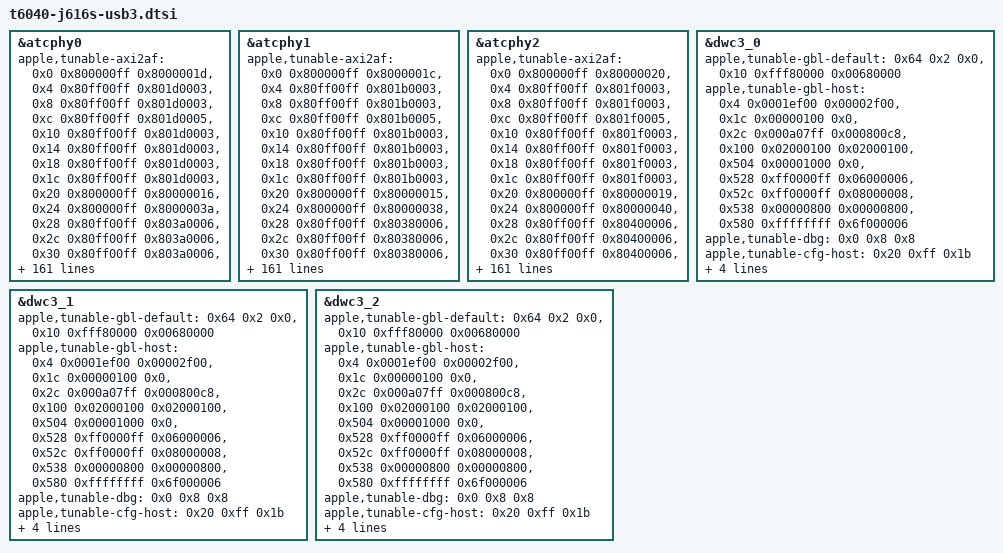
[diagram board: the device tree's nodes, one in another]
// SPDX-License-Identifier: GPL-2.0+ OR MIT
/*
 * USB3 tunables of the J616s Type-C ports, from this machine's ADT (macOS 26.6.2, 2026-10-16):
 * the atc-phyN tables AppleT6040TypeCPhy applies at every USB3 power-on, relative to the PHY
 * region each one targets, and the usb-drdN controller tables (identical on the three ports).
 * Entries are <offset mask value>: new = (old & ~mask) | value.
 */

&atcphy0 {
	apple,tunable-axi2af =
		<0x0 0x800000ff 0x8000001d>,
		<0x4 0x80ff00ff 0x801d0003>,
		<0x8 0x80ff00ff 0x801d0003>,
		<0xc 0x80ff00ff 0x801d0005>,
		<0x10 0x80ff00ff 0x801d0003>,
		<0x14 0x80ff00ff 0x801d0003>,
		<0x18 0x80ff00ff 0x801d0003>,
		<0x1c 0x80ff00ff 0x801d0003>,
		<0x20 0x800000ff 0x80000016>,
		<0x24 0x800000ff 0x8000003a>,
		<0x28 0x80ff00ff 0x803a0006>,
		<0x2c 0x80ff00ff 0x803a0006>,
		<0x30 0x80ff00ff 0x803a0006>,
		<0x34 0x80ff00ff 0x803a0006>,
		<0x38 0x80ff00ff 0x803a0006>,
		<0x3c 0x80ff00ff 0x803a0006>,
		<0x40 0x800000ff 0x80000016>,
		<0x44 0x800000ff 0x80000016>,
		<0x48 0x800000ff 0x80000016>,
		<0x100 0x000000ff 0x000000ff>,
		<0x108 0xffff0006 0x00100000>,
		<0x304 0x3f3f0000 0x04040000>,
		<0x308 0x000fffff 0x00001681>,
		<0x30c 0x000fffff 0x00001680>,
		<0x310 0x70000fff 0x000001e0>,
		<0x314 0xf0000fff 0x800001e0>,
		<0x318 0x70000fff 0x000001e0>,
		<0x31c 0xf0000fff 0x800001e0>,
		<0x320 0x70000fff 0x000005a0>,
		<0x324 0xf0000fff 0x800005a0>,
		<0x328 0x70000fff 0x000005a0>,
		<0x32c 0xf0000fff 0x800005a0>,
		<0x330 0x70000fff 0x000005a0>,
		<0x334 0xf0000fff 0x800005a0>,
		<0x338 0x70000fff 0x000005a0>,
		<0x33c 0x70000fff 0x000005a0>,
		<0x340 0x70000fff 0x000005a0>,
		<0x344 0x70000fff 0x000005a0>,
		<0x348 0x70000fff 0x000005a0>,
		<0x34c 0x70000fff 0x000005a0>,
		<0x350 0x70000fff 0x000005a0>,
		<0x358 0xffffffff 0x0000ffff>,
		<0x35c 0xffffffff 0x0000ffff>,
		<0x408 0xffff0020 0x00190020>,
		<0x40c 0x000fffff 0x00001681>,
		<0x410 0x000fffff 0x00001680>,
		<0x414 0x70000fff 0x000001e0>,
		<0x418 0x70000fff 0x000001e0>,
		<0x41c 0x70000fff 0x000001e0>,
		<0x420 0x70000fff 0x000001e0>,
		<0x424 0x70000fff 0x000005a0>,
		<0x428 0x70000fff 0x000005a0>,
		<0x42c 0x70000fff 0x000005a0>,
		<0x430 0x70000fff 0x000005a0>,
		<0x434 0x70000fff 0x000005a0>,
		<0x438 0x70000fff 0x000005a0>,
		<0x43c 0x70000fff 0x000005a0>,
		<0x440 0x70000fff 0x000005a0>,
		<0x444 0x70000fff 0x000005a0>,
		<0x448 0x70000fff 0x000005a0>,
		<0x44c 0x70000fff 0x000005a0>,
		<0x450 0x70000fff 0x000005a0>,
		<0x454 0x70000fff 0x000005a0>,
		<0x948 0x07ff07ff 0x00280000>,
		<0xa48 0x07ff07ff 0x00400040>,
		<0xb48 0x07ff07ff 0x00b8010e>,
		<0xc48 0x07ff07ff 0x00400020>,
		<0xd48 0x07ff07ff 0x008a008a>,
		<0x1000 0xffffffff 0x7fffffff>,
		<0x4008 0x00000001 0x00000001>,
		<0x400c 0x00000001 0x00000001>,
		<0x4014 0x00000001 0x00000001>,
		<0x4018 0x00000001 0x00000000>,
		<0x401c 0x00000001 0x00000001>;
	apple,tunable-fabric =
		<0x4 0x003f003f 0x00200020>,
		<0xc 0x000000f1 0x000000a1>,
		<0x10 0x0000801f 0x00000004>,
		<0x18 0x003f003f 0x00200020>,
		<0x20 0x000000f1 0x000000a1>,
		<0x24 0x0000801f 0x00000004>,
		<0x2c 0x00ff00ff 0x00960096>,
		<0x34 0x000000f1 0x00000071>,
		<0x38 0x0000801f 0x00000004>,
		<0x40 0x0000003f 0x00000020>,
		<0x48 0x0000801f 0x00000004>,
		<0x50 0x007f007f 0x00450045>,
		<0x58 0x0000801f 0x00000004>,
		<0x60 0x0000003f 0x00000020>,
		<0x68 0x0000801f 0x00000004>,
		<0x70 0x00000001 0x00000001>,
		<0x74 0x0000801f 0x00000004>,
		<0x7c 0x007f007f 0x00400040>,
		<0x80 0x000000f1 0x00000011>,
		<0x84 0x00000001 0x00000001>,
		<0x88 0x00000001 0x00000001>,
		<0x8c 0x0000801f 0x00000004>,
		<0x94 0x001f001f 0x00100010>,
		<0x98 0x000000f1 0x00000011>,
		<0x9c 0x0000801f 0x00000004>,
		<0xa4 0x000000ff 0x000000e0>,
		<0xa8 0x0000801f 0x00000004>,
		<0xb0 0x0000003f 0x00000020>,
		<0xb8 0x0000801f 0x00000004>,
		<0xc0 0x0000003f 0x00000020>,
		<0xc8 0x0000801f 0x00000004>,
		<0xd0 0x001f001f 0x00100010>,
		<0xd8 0x00000001 0x00000001>,
		<0xdc 0x00000001 0x00000001>,
		<0xe0 0x0000801f 0x00000004>,
		<0xe8 0x0000000f 0x00000008>,
		<0xec 0x0000801f 0x00000004>,
		<0xf4 0xffffffff 0x01010101>,
		<0xf8 0x0000801f 0x00000004>,
		<0x100 0x00000001 0x00000001>,
		<0x104 0x00000001 0x00000001>,
		<0x108 0x0000801f 0x00000004>,
		<0x110 0x0000801f 0x00000004>,
		<0x118 0x0000801f 0x00000004>,
		<0x120 0x00000001 0x00000001>,
		<0x124 0x00000001 0x00000001>,
		<0x128 0x0000801f 0x00000004>,
		<0x130 0xffffffff 0x01010101>,
		<0x134 0x0000801f 0x00000004>,
		<0x13c 0x00000001 0x00000001>,
		<0x140 0x00000001 0x00000001>,
		<0x144 0x0000801f 0x00000004>,
		<0x14c 0x00000001 0x00000001>,
		<0x150 0x00000001 0x00000001>,
		<0x154 0x0000801f 0x00000004>,
		<0x15c 0x0000801f 0x00000004>,
		<0x164 0xffffffff 0x01010101>,
		<0x168 0x0000ffff 0x00000101>,
		<0x16c 0x0000801f 0x00000004>,
		<0x174 0x00000001 0x00000001>,
		<0x178 0x00000001 0x00000001>,
		<0x17c 0x0000801f 0x00000004>,
		<0x184 0x00000001 0x00000001>,
		<0x188 0x00000001 0x00000001>,
		<0x18c 0x0000801f 0x00000004>;
	apple,tunable-common-cfg =
		<0x8 0x00000001 0x00000001>;
	apple,tunable-axi2af-lioa =
		<0x28 0x0000fe2f 0x00000000>,
		<0x2c 0x00000007 0x00000000>,
		<0x30 0x0000007f 0x00000000>,
		<0x34 0x000000ff 0x00000000>,
		<0x58 0x0000010b 0x00000000>;
	apple,tunable-lane0 =
		<0xd094 0x00080000 0x00080000>,
		<0xd098 0x00080000 0x00080000>,
		<0xd0a4 0x00800000 0x00800000>,
		<0xd0a8 0x00200000 0x00200000>;
	apple,tunable-lane1 =
		<0x1d094 0x00080000 0x00080000>,
		<0x1d098 0x00080000 0x00080000>,
		<0x1d0a4 0x00800000 0x00800000>,
		<0x1d0a8 0x00200000 0x00200000>;
	apple,tunable-aus40cmn-shm =
		<0xa04 0x0000007c 0x00000048>;
	apple,tunable-auspll =
		<0x3224 0x00000c00 0x00000800>,
		<0x3230 0x0000001f 0x0000000f>,
		<0x3240 0x07d8007f 0x04000059>,
		<0x32b0 0x0b800000 0x01800000>,
		<0x32e8 0x00060001 0x00040001>,
		<0x3338 0x0f800000 0x07800000>;
	apple,tunable-cio4pll =
		<0x3a30 0x0000001f 0x0000000f>,
		<0x3a4c 0x0000fe7f 0x0000501e>,
		<0x3ab0 0x00700000 0x00300000>,
		<0x3ae8 0x00060000 0x00020000>;
	apple,tunable-pipehandler = <0x44 0x4 0x4>;
	/* ADT tunable_USB2PHY_HOST, relative to USB2 bank 0. */
	apple,tunable-usb2-host = <0x8 0x7003 0x3>;
};

&atcphy1 {
	apple,tunable-axi2af =
		<0x0 0x800000ff 0x8000001c>,
		<0x4 0x80ff00ff 0x801b0003>,
		<0x8 0x80ff00ff 0x801b0003>,
		<0xc 0x80ff00ff 0x801b0005>,
		<0x10 0x80ff00ff 0x801b0003>,
		<0x14 0x80ff00ff 0x801b0003>,
		<0x18 0x80ff00ff 0x801b0003>,
		<0x1c 0x80ff00ff 0x801b0003>,
		<0x20 0x800000ff 0x80000015>,
		<0x24 0x800000ff 0x80000038>,
		<0x28 0x80ff00ff 0x80380006>,
		<0x2c 0x80ff00ff 0x80380006>,
		<0x30 0x80ff00ff 0x80380006>,
		<0x34 0x80ff00ff 0x80380006>,
		<0x38 0x80ff00ff 0x80380006>,
		<0x3c 0x80ff00ff 0x80380006>,
		<0x40 0x800000ff 0x80000015>,
		<0x44 0x800000ff 0x80000015>,
		<0x48 0x800000ff 0x80000015>,
		<0x100 0x000000ff 0x000000ff>,
		<0x108 0xffff0006 0x00100000>,
		<0x304 0x3f3f0000 0x04040000>,
		<0x308 0x000fffff 0x00001681>,
		<0x30c 0x000fffff 0x00001680>,
		<0x310 0x70000fff 0x000001e0>,
		<0x314 0xf0000fff 0x800001e0>,
		<0x318 0x70000fff 0x000001e0>,
		<0x31c 0xf0000fff 0x800001e0>,
		<0x320 0x70000fff 0x000005a0>,
		<0x324 0xf0000fff 0x800005a0>,
		<0x328 0x70000fff 0x000005a0>,
		<0x32c 0xf0000fff 0x800005a0>,
		<0x330 0x70000fff 0x000005a0>,
		<0x334 0xf0000fff 0x800005a0>,
		<0x338 0x70000fff 0x000005a0>,
		<0x33c 0x70000fff 0x000005a0>,
		<0x340 0x70000fff 0x000005a0>,
		<0x344 0x70000fff 0x000005a0>,
		<0x348 0x70000fff 0x000005a0>,
		<0x34c 0x70000fff 0x000005a0>,
		<0x350 0x70000fff 0x000005a0>,
		<0x358 0xffffffff 0x0000ffff>,
		<0x35c 0xffffffff 0x0000ffff>,
		<0x408 0xffff0020 0x00180020>,
		<0x40c 0x000fffff 0x00001681>,
		<0x410 0x000fffff 0x00001680>,
		<0x414 0x70000fff 0x000001e0>,
		<0x418 0x70000fff 0x000001e0>,
		<0x41c 0x70000fff 0x000001e0>,
		<0x420 0x70000fff 0x000001e0>,
		<0x424 0x70000fff 0x000005a0>,
		<0x428 0x70000fff 0x000005a0>,
		<0x42c 0x70000fff 0x000005a0>,
		<0x430 0x70000fff 0x000005a0>,
		<0x434 0x70000fff 0x000005a0>,
		<0x438 0x70000fff 0x000005a0>,
		<0x43c 0x70000fff 0x000005a0>,
		<0x440 0x70000fff 0x000005a0>,
		<0x444 0x70000fff 0x000005a0>,
		<0x448 0x70000fff 0x000005a0>,
		<0x44c 0x70000fff 0x000005a0>,
		<0x450 0x70000fff 0x000005a0>,
		<0x454 0x70000fff 0x000005a0>,
		<0x948 0x07ff07ff 0x00280000>,
		<0xa48 0x07ff07ff 0x00400040>,
		<0xb48 0x07ff07ff 0x00b8010e>,
		<0xc48 0x07ff07ff 0x00400020>,
		<0xd48 0x07ff07ff 0x008a008a>,
		<0x1000 0xffffffff 0x7fffffff>,
		<0x4008 0x00000001 0x00000001>,
		<0x400c 0x00000001 0x00000001>,
		<0x4014 0x00000001 0x00000001>,
		<0x4018 0x00000001 0x00000000>,
		<0x401c 0x00000001 0x00000001>;
	apple,tunable-fabric =
		<0x4 0x003f003f 0x00200020>,
		<0xc 0x000000f1 0x000000a1>,
		<0x10 0x0000801f 0x00000004>,
		<0x18 0x003f003f 0x00200020>,
		<0x20 0x000000f1 0x000000a1>,
		<0x24 0x0000801f 0x00000004>,
		<0x2c 0x00ff00ff 0x00960096>,
		<0x34 0x000000f1 0x00000071>,
		<0x38 0x0000801f 0x00000004>,
		<0x40 0x0000003f 0x00000020>,
		<0x48 0x0000801f 0x00000004>,
		<0x50 0x007f007f 0x00450045>,
		<0x58 0x0000801f 0x00000004>,
		<0x60 0x0000003f 0x00000020>,
		<0x68 0x0000801f 0x00000004>,
		<0x70 0x00000001 0x00000001>,
		<0x74 0x0000801f 0x00000004>,
		<0x7c 0x007f007f 0x00400040>,
		<0x80 0x000000f1 0x00000011>,
		<0x84 0x00000001 0x00000001>,
		<0x88 0x00000001 0x00000001>,
		<0x8c 0x0000801f 0x00000004>,
		<0x94 0x001f001f 0x00100010>,
		<0x98 0x000000f1 0x00000011>,
		<0x9c 0x0000801f 0x00000004>,
		<0xa4 0x000000ff 0x000000e0>,
		<0xa8 0x0000801f 0x00000004>,
		<0xb0 0x0000003f 0x00000020>,
		<0xb8 0x0000801f 0x00000004>,
		<0xc0 0x0000003f 0x00000020>,
		<0xc8 0x0000801f 0x00000004>,
		<0xd0 0x001f001f 0x00100010>,
		<0xd8 0x00000001 0x00000001>,
		<0xdc 0x00000001 0x00000001>,
		<0xe0 0x0000801f 0x00000004>,
		<0xe8 0x0000000f 0x00000008>,
		<0xec 0x0000801f 0x00000004>,
		<0xf4 0xffffffff 0x01010101>,
		<0xf8 0x0000801f 0x00000004>,
		<0x100 0x00000001 0x00000001>,
		<0x104 0x00000001 0x00000001>,
		<0x108 0x0000801f 0x00000004>,
		<0x110 0x0000801f 0x00000004>,
		<0x118 0x0000801f 0x00000004>,
		<0x120 0x00000001 0x00000001>,
		<0x124 0x00000001 0x00000001>,
		<0x128 0x0000801f 0x00000004>,
		<0x130 0xffffffff 0x01010101>,
		<0x134 0x0000801f 0x00000004>,
		<0x13c 0x00000001 0x00000001>,
		<0x140 0x00000001 0x00000001>,
		<0x144 0x0000801f 0x00000004>,
		<0x14c 0x00000001 0x00000001>,
		<0x150 0x00000001 0x00000001>,
		<0x154 0x0000801f 0x00000004>,
		<0x15c 0x0000801f 0x00000004>,
		<0x164 0xffffffff 0x01010101>,
		<0x168 0x0000ffff 0x00000101>,
		<0x16c 0x0000801f 0x00000004>,
		<0x174 0x00000001 0x00000001>,
		<0x178 0x00000001 0x00000001>,
		<0x17c 0x0000801f 0x00000004>,
		<0x184 0x00000001 0x00000001>,
		<0x188 0x00000001 0x00000001>,
		<0x18c 0x0000801f 0x00000004>;
	apple,tunable-common-cfg =
		<0x8 0x00000001 0x00000001>;
	apple,tunable-axi2af-lioa =
		<0x28 0x0000fe2f 0x00000000>,
		<0x2c 0x00000007 0x00000000>,
		<0x30 0x0000007f 0x00000000>,
		<0x34 0x000000ff 0x00000000>,
		<0x58 0x0000010b 0x00000000>;
	apple,tunable-lane0 =
		<0xd094 0x00080000 0x00080000>,
		<0xd098 0x00080000 0x00080000>,
		<0xd0a4 0x00800000 0x00800000>,
		<0xd0a8 0x00200000 0x00200000>;
	apple,tunable-lane1 =
		<0x1d094 0x00080000 0x00080000>,
		<0x1d098 0x00080000 0x00080000>,
		<0x1d0a4 0x00800000 0x00800000>,
		<0x1d0a8 0x00200000 0x00200000>;
	apple,tunable-aus40cmn-shm =
		<0xa04 0x0000007c 0x0000004c>;
	apple,tunable-auspll =
		<0x3224 0x00000c00 0x00000800>,
		<0x3230 0x0000001f 0x0000000f>,
		<0x3240 0x07d8007f 0x04000049>,
		<0x32b0 0x0b800000 0x01800000>,
		<0x32e8 0x00060001 0x00040001>,
		<0x3338 0x0f800000 0x07800000>;
	apple,tunable-cio4pll =
		<0x3a30 0x0000001f 0x0000000f>,
		<0x3a4c 0x0000fe7f 0x0000501e>,
		<0x3ab0 0x00700000 0x00300000>,
		<0x3ae8 0x00060000 0x00020000>;
	apple,tunable-pipehandler = <0x44 0x4 0x4>;
	/* ADT tunable_USB2PHY_HOST, relative to USB2 bank 0. */
	apple,tunable-usb2-host = <0x8 0x7003 0x3>;
};

&atcphy2 {
	apple,tunable-axi2af =
		<0x0 0x800000ff 0x80000020>,
		<0x4 0x80ff00ff 0x801f0003>,
		<0x8 0x80ff00ff 0x801f0003>,
		<0xc 0x80ff00ff 0x801f0005>,
		<0x10 0x80ff00ff 0x801f0003>,
		<0x14 0x80ff00ff 0x801f0003>,
		<0x18 0x80ff00ff 0x801f0003>,
		<0x1c 0x80ff00ff 0x801f0003>,
		<0x20 0x800000ff 0x80000019>,
		<0x24 0x800000ff 0x80000040>,
		<0x28 0x80ff00ff 0x80400006>,
		<0x2c 0x80ff00ff 0x80400006>,
		<0x30 0x80ff00ff 0x80400006>,
		<0x34 0x80ff00ff 0x80400006>,
		<0x38 0x80ff00ff 0x80400006>,
		<0x3c 0x80ff00ff 0x80400006>,
		<0x40 0x800000ff 0x80000019>,
		<0x44 0x800000ff 0x80000019>,
		<0x48 0x800000ff 0x80000019>,
		<0x100 0x000000ff 0x000000ff>,
		<0x108 0xffff0006 0x00100000>,
		<0x304 0x3f3f0000 0x04040000>,
		<0x308 0x000fffff 0x00001681>,
		<0x30c 0x000fffff 0x00001680>,
		<0x310 0x70000fff 0x000001e0>,
		<0x314 0xf0000fff 0x800001e0>,
		<0x318 0x70000fff 0x000001e0>,
		<0x31c 0xf0000fff 0x800001e0>,
		<0x320 0x70000fff 0x000005a0>,
		<0x324 0xf0000fff 0x800005a0>,
		<0x328 0x70000fff 0x000005a0>,
		<0x32c 0xf0000fff 0x800005a0>,
		<0x330 0x70000fff 0x000005a0>,
		<0x334 0xf0000fff 0x800005a0>,
		<0x338 0x70000fff 0x000005a0>,
		<0x33c 0x70000fff 0x000005a0>,
		<0x340 0x70000fff 0x000005a0>,
		<0x344 0x70000fff 0x000005a0>,
		<0x348 0x70000fff 0x000005a0>,
		<0x34c 0x70000fff 0x000005a0>,
		<0x350 0x70000fff 0x000005a0>,
		<0x358 0xffffffff 0x0000ffff>,
		<0x35c 0xffffffff 0x0000ffff>,
		<0x408 0xffff0020 0x001c0020>,
		<0x40c 0x000fffff 0x00001681>,
		<0x410 0x000fffff 0x00001680>,
		<0x414 0x70000fff 0x000001e0>,
		<0x418 0x70000fff 0x000001e0>,
		<0x41c 0x70000fff 0x000001e0>,
		<0x420 0x70000fff 0x000001e0>,
		<0x424 0x70000fff 0x000005a0>,
		<0x428 0x70000fff 0x000005a0>,
		<0x42c 0x70000fff 0x000005a0>,
		<0x430 0x70000fff 0x000005a0>,
		<0x434 0x70000fff 0x000005a0>,
		<0x438 0x70000fff 0x000005a0>,
		<0x43c 0x70000fff 0x000005a0>,
		<0x440 0x70000fff 0x000005a0>,
		<0x444 0x70000fff 0x000005a0>,
		<0x448 0x70000fff 0x000005a0>,
		<0x44c 0x70000fff 0x000005a0>,
		<0x450 0x70000fff 0x000005a0>,
		<0x454 0x70000fff 0x000005a0>,
		<0x948 0x07ff07ff 0x00280000>,
		<0xa48 0x07ff07ff 0x00400040>,
		<0xb48 0x07ff07ff 0x00b8010e>,
		<0xc48 0x07ff07ff 0x00400020>,
		<0xd48 0x07ff07ff 0x008a008a>,
		<0x1000 0xffffffff 0x7fffffff>,
		<0x4008 0x00000001 0x00000001>,
		<0x400c 0x00000001 0x00000001>,
		<0x4014 0x00000001 0x00000001>,
		<0x4018 0x00000001 0x00000000>,
		<0x401c 0x00000001 0x00000001>;
	apple,tunable-fabric =
		<0x4 0x003f003f 0x00200020>,
		<0xc 0x000000f1 0x000000a1>,
		<0x10 0x0000801f 0x00000004>,
		<0x18 0x003f003f 0x00200020>,
		<0x20 0x000000f1 0x000000a1>,
		<0x24 0x0000801f 0x00000004>,
		<0x2c 0x00ff00ff 0x00960096>,
		<0x34 0x000000f1 0x00000071>,
		<0x38 0x0000801f 0x00000004>,
		<0x40 0x0000003f 0x00000020>,
		<0x48 0x0000801f 0x00000004>,
		<0x50 0x007f007f 0x00450045>,
		<0x58 0x0000801f 0x00000004>,
		<0x60 0x0000003f 0x00000020>,
		<0x68 0x0000801f 0x00000004>,
		<0x70 0x00000001 0x00000001>,
		<0x74 0x0000801f 0x00000004>,
		<0x7c 0x007f007f 0x00400040>,
		<0x80 0x000000f1 0x00000011>,
		<0x84 0x00000001 0x00000001>,
		<0x88 0x00000001 0x00000001>,
		<0x8c 0x0000801f 0x00000004>,
		<0x94 0x001f001f 0x00100010>,
		<0x98 0x000000f1 0x00000011>,
		<0x9c 0x0000801f 0x00000004>,
		<0xa4 0x000000ff 0x000000e0>,
		<0xa8 0x0000801f 0x00000004>,
		<0xb0 0x0000003f 0x00000020>,
		<0xb8 0x0000801f 0x00000004>,
		<0xc0 0x0000003f 0x00000020>,
		<0xc8 0x0000801f 0x00000004>,
		<0xd0 0x001f001f 0x00100010>,
		<0xd8 0x00000001 0x00000001>,
		<0xdc 0x00000001 0x00000001>,
		<0xe0 0x0000801f 0x00000004>,
		<0xe8 0x0000000f 0x00000008>,
		<0xec 0x0000801f 0x00000004>,
		<0xf4 0xffffffff 0x01010101>,
		<0xf8 0x0000801f 0x00000004>,
		<0x100 0x00000001 0x00000001>,
		<0x104 0x00000001 0x00000001>,
		<0x108 0x0000801f 0x00000004>,
		<0x110 0x0000801f 0x00000004>,
		<0x118 0x0000801f 0x00000004>,
		<0x120 0x00000001 0x00000001>,
		<0x124 0x00000001 0x00000001>,
		<0x128 0x0000801f 0x00000004>,
		<0x130 0xffffffff 0x01010101>,
		<0x134 0x0000801f 0x00000004>,
		<0x13c 0x00000001 0x00000001>,
		<0x140 0x00000001 0x00000001>,
		<0x144 0x0000801f 0x00000004>,
		<0x14c 0x00000001 0x00000001>,
		<0x150 0x00000001 0x00000001>,
		<0x154 0x0000801f 0x00000004>,
		<0x15c 0x0000801f 0x00000004>,
		<0x164 0xffffffff 0x01010101>,
		<0x168 0x0000ffff 0x00000101>,
		<0x16c 0x0000801f 0x00000004>,
		<0x174 0x00000001 0x00000001>,
		<0x178 0x00000001 0x00000001>,
		<0x17c 0x0000801f 0x00000004>,
		<0x184 0x00000001 0x00000001>,
		<0x188 0x00000001 0x00000001>,
		<0x18c 0x0000801f 0x00000004>;
	apple,tunable-common-cfg =
		<0x8 0x00000001 0x00000001>;
	apple,tunable-axi2af-lioa =
		<0x28 0x0000fe2f 0x00000000>,
		<0x2c 0x00000007 0x00000000>,
		<0x30 0x0000007f 0x00000000>,
		<0x34 0x000000ff 0x00000000>,
		<0x58 0x0000010b 0x00000000>;
	apple,tunable-lane0 =
		<0xd094 0x00080000 0x00080000>,
		<0xd098 0x00080000 0x00080000>,
		<0xd0a4 0x00800000 0x00800000>,
		<0xd0a8 0x00200000 0x00200000>;
	apple,tunable-lane1 =
		<0x1d094 0x00080000 0x00080000>,
		<0x1d098 0x00080000 0x00080000>,
		<0x1d0a4 0x00800000 0x00800000>,
		<0x1d0a8 0x00200000 0x00200000>;
	apple,tunable-aus40cmn-shm =
		<0xa04 0x0000007c 0x00000058>;
	apple,tunable-auspll =
		<0x3224 0x00000c00 0x00000800>,
		<0x3230 0x0000001f 0x0000000f>,
		<0x3240 0x07d8007f 0x04000049>,
		<0x32b0 0x0b800000 0x01800000>,
		<0x32e8 0x00060001 0x00040001>,
		<0x3338 0x0f800000 0x07800000>;
	apple,tunable-cio4pll =
		<0x3a30 0x0000001f 0x0000000f>,
		<0x3a4c 0x0000fe7f 0x00005220>,
		<0x3ab0 0x00700000 0x00300000>,
		<0x3ae8 0x00060000 0x00020000>;
	apple,tunable-pipehandler = <0x44 0x4 0x4>;
	/* ADT tunable_USB2PHY_HOST, relative to USB2 bank 0. */
	apple,tunable-usb2-host = <0x8 0x7003 0x3>;
};

&dwc3_0 {
	/* DRD_USB31_GBL_DEFAULT, then GCTL.PWRDNSCALE = 0xd as macOS's controller reset() sets it */
	apple,tunable-gbl-default = <0x64 0x2 0x0>, <0x10 0xfff80000 0x00680000>;
	apple,tunable-gbl-host = <0x4 0x0001ef00 0x00002f00>, <0x1c 0x00000100 0x0>,
		<0x2c 0x000a07ff 0x000800c8>, <0x100 0x02000100 0x02000100>,
		<0x504 0x00001000 0x0>, <0x528 0xff0000ff 0x06000006>,
		<0x52c 0xff0000ff 0x08000008>, <0x538 0x00000800 0x00000800>,
		<0x580 0xffffffff 0x6f000006>;
	apple,tunable-dbg = <0x0 0x8 0x8>;
	apple,tunable-cfg-host = <0x20 0xff 0x1b>;
	apple,tunable-link = <0x20 0x7ff00000 0x4e900000>, <0x24 0x001f8000 0x000b8000>,
		<0x60 0x0003ffff 0x00000600>;
};

&dwc3_1 {
	/* DRD_USB31_GBL_DEFAULT, then GCTL.PWRDNSCALE = 0xd as macOS's controller reset() sets it */
	apple,tunable-gbl-default = <0x64 0x2 0x0>, <0x10 0xfff80000 0x00680000>;
	apple,tunable-gbl-host = <0x4 0x0001ef00 0x00002f00>, <0x1c 0x00000100 0x0>,
		<0x2c 0x000a07ff 0x000800c8>, <0x100 0x02000100 0x02000100>,
		<0x504 0x00001000 0x0>, <0x528 0xff0000ff 0x06000006>,
		<0x52c 0xff0000ff 0x08000008>, <0x538 0x00000800 0x00000800>,
		<0x580 0xffffffff 0x6f000006>;
	apple,tunable-dbg = <0x0 0x8 0x8>;
	apple,tunable-cfg-host = <0x20 0xff 0x1b>;
	apple,tunable-link = <0x20 0x7ff00000 0x4e900000>, <0x24 0x001f8000 0x000b8000>,
		<0x60 0x0003ffff 0x00000600>;
};

&dwc3_2 {
	/* DRD_USB31_GBL_DEFAULT, then GCTL.PWRDNSCALE = 0xd as macOS's controller reset() sets it */
	apple,tunable-gbl-default = <0x64 0x2 0x0>, <0x10 0xfff80000 0x00680000>;
	apple,tunable-gbl-host = <0x4 0x0001ef00 0x00002f00>, <0x1c 0x00000100 0x0>,
		<0x2c 0x000a07ff 0x000800c8>, <0x100 0x02000100 0x02000100>,
		<0x504 0x00001000 0x0>, <0x528 0xff0000ff 0x06000006>,
		<0x52c 0xff0000ff 0x08000008>, <0x538 0x00000800 0x00000800>,
		<0x580 0xffffffff 0x6f000006>;
	apple,tunable-dbg = <0x0 0x8 0x8>;
	apple,tunable-cfg-host = <0x20 0xff 0x1b>;
	apple,tunable-link = <0x20 0x7ff00000 0x4e900000>, <0x24 0x001f8000 0x000b8000>,
		<0x60 0x0003ffff 0x00000600>;
};
